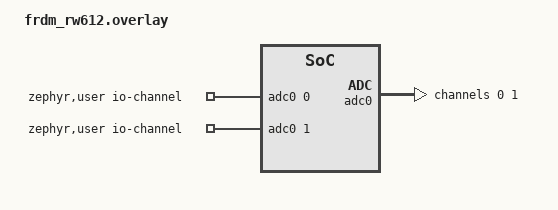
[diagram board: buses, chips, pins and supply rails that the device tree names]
/*
 * Copyright 2023 NXP
 * SPDX-License-Identifier: Apache-2.0
 */

#include <zephyr/dt-bindings/adc/nxp,gau-adc.h>

/ {
	zephyr,user {
		/* adjust channel number according to pinmux in board.dts */
		io-channels = <&adc0 0 &adc0 1>;
	};
};

&adc0 {
	#address-cells = <1>;
	#size-cells = <0>;

	channel@0 {
		reg = <0>;
		zephyr,gain = "ADC_GAIN_1";
		zephyr,reference = "ADC_REF_VDD_1";
		zephyr,vref-mv = <1800>;
		zephyr,acquisition-time = <ADC_ACQ_TIME_DEFAULT>;
		zephyr,resolution = <16>;
		zephyr,input-positive = <GAU_ADC_CH0>;
	};

	channel@1 {
		reg = <1>;
		zephyr,gain = "ADC_GAIN_1";
		zephyr,reference = "ADC_REF_VDD_1";
		zephyr,vref-mv = <1800>;
		zephyr,acquisition-time = <ADC_ACQ_TIME_DEFAULT>;
		zephyr,resolution = <16>;
		zephyr,input-positive = <GAU_ADC_CH1>;
	};
};
